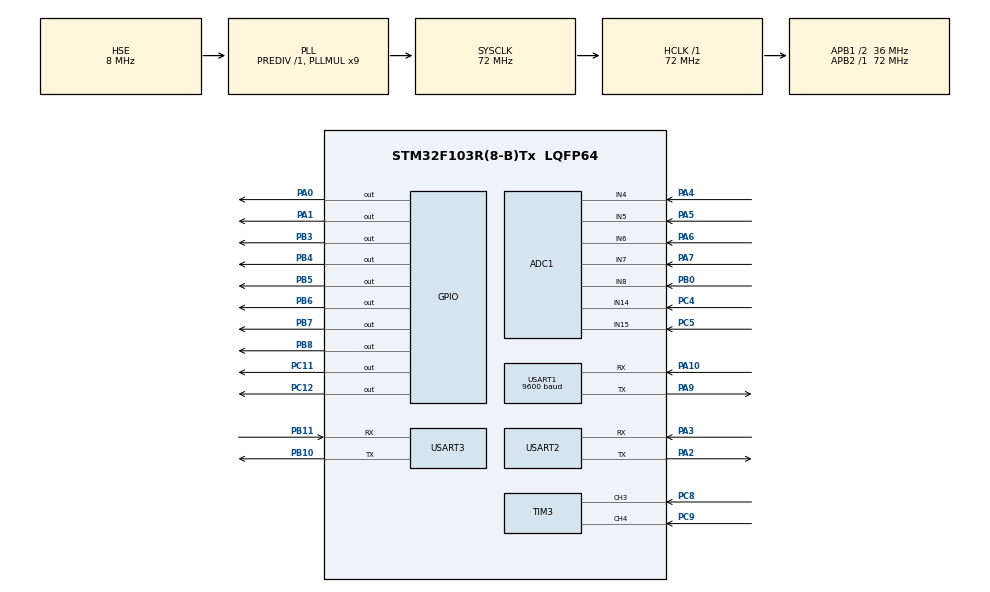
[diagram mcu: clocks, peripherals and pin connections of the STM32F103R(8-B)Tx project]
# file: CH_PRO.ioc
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ADC1.Channel-10\#ChannelRegularConversion=ADC_CHANNEL_6
ADC1.Channel-11\#ChannelRegularConversion=ADC_CHANNEL_7
ADC1.Channel-12\#ChannelRegularConversion=ADC_CHANNEL_8
ADC1.Channel-13\#ChannelRegularConversion=ADC_CHANNEL_14
ADC1.Channel-14\#ChannelRegularConversion=ADC_CHANNEL_15
ADC1.Channel-8\#ChannelRegularConversion=ADC_CHANNEL_4
ADC1.Channel-9\#ChannelRegularConversion=ADC_CHANNEL_5
ADC1.ContinuousConvMode=ENABLE
ADC1.DataAlign=ADC_DATAALIGN_RIGHT
ADC1.DiscontinuousConvMode=DISABLE
ADC1.EnableAnalogWatchDog=false
ADC1.EnableRegularConversion=ENABLE
ADC1.ExternalTrigConv=ADC_SOFTWARE_START
ADC1.InjNumberOfConversion=0
ADC1.NbrOfConversion=7
ADC1.NbrOfConversionFlag=1
ADC1.Rank-10\#ChannelRegularConversion=3
ADC1.Rank-11\#ChannelRegularConversion=4
ADC1.Rank-12\#ChannelRegularConversion=5
ADC1.Rank-13\#ChannelRegularConversion=6
ADC1.Rank-14\#ChannelRegularConversion=7
ADC1.Rank-8\#ChannelRegularConversion=1
ADC1.Rank-9\#ChannelRegularConversion=2
ADC1.SamplingTime-10\#ChannelRegularConversion=ADC_SAMPLETIME_28CYCLES_5
ADC1.SamplingTime-11\#ChannelRegularConversion=ADC_SAMPLETIME_28CYCLES_5
ADC1.SamplingTime-12\#ChannelRegularConversion=ADC_SAMPLETIME_28CYCLES_5
ADC1.SamplingTime-13\#ChannelRegularConversion=ADC_SAMPLETIME_28CYCLES_5
ADC1.SamplingTime-14\#ChannelRegularConversion=ADC_SAMPLETIME_28CYCLES_5
ADC1.SamplingTime-8\#ChannelRegularConversion=ADC_SAMPLETIME_28CYCLES_5
ADC1.SamplingTime-9\#ChannelRegularConversion=ADC_SAMPLETIME_28CYCLES_5
ADC1.ScanConvMode=ADC_SCAN_ENABLE
ADC1.master=1
Dma.Request0=USART1_RX
Dma.Request1=USART1_TX
Dma.USART1_RX.0.Direction=DMA_PERIPH_TO_MEMORY
Dma.USART1_RX.0.Instance=DMA1_Channel5
Dma.USART1_RX.0.MemDataAlignment=DMA_MDATAALIGN_BYTE
Dma.USART1_RX.0.MemInc=DMA_MINC_ENABLE
Dma.USART1_RX.0.Mode=DMA_NORMAL
Dma.USART1_RX.0.PeriphDataAlignment=DMA_PDATAALIGN_BYTE
Dma.USART1_RX.0.PeriphInc=DMA_PINC_DISABLE
Dma.USART1_RX.0.Priority=DMA_PRIORITY_VERY_HIGH
Dma.USART1_TX.1.Direction=DMA_MEMORY_TO_PERIPH
Dma.USART1_TX.1.Instance=DMA1_Channel4
Dma.USART1_TX.1.MemDataAlignment=DMA_MDATAALIGN_BYTE
Dma.USART1_TX.1.MemInc=DMA_MINC_ENABLE
Dma.USART1_TX.1.Mode=DMA_NORMAL
Dma.USART1_TX.1.PeriphDataAlignment=DMA_PDATAALIGN_BYTE
Dma.USART1_TX.1.PeriphInc=DMA_PINC_DISABLE
Dma.USART1_TX.1.Priority=DMA_PRIORITY_LOW
FREERTOS.INCLUDE_eTaskGetState=1
FREERTOS.Mutexes01=sendCmd,Dynamic,NULL
FREERTOS.Tasks01=helloTask,0,128,StartHelloTask,Default,NULL,Dynamic,NULL,NULL;cmdTask,-3,128,StartCmdTask,Default,NULL,Dynamic,NULL,NULL
FREERTOS.Timers01=myTimer01,Callback01,osTimerPeriodic,Default,NULL,Dynamic,NULL;myTimer02,Callback02,osTimerPeriodic,Default,NULL,Dynamic,NULL;myTimer03,Callback03,osTimerPeriodic,Default,NULL,Dynamic,NULL
FREERTOS.configTIMER_TASK_STACK_DEPTH=128
FREERTOS.configUSE_TIMERS=1
Mcu.Family=STM32F1
Mcu.Name=STM32F103R(8-B)Tx
Mcu.Package=LQFP64
NVIC.DMA1_Channel4_IRQn=true\:5\:0\:false\:false\:true\:true\:false
NVIC.DMA1_Channel5_IRQn=true\:5\:0\:false\:false\:true\:true\:false
NVIC.PriorityGroup=NVIC_PRIORITYGROUP_4
NVIC.TIM1_BRK_IRQn=true\:5\:0\:false\:false\:true\:true\:true
NVIC.TIM3_IRQn=true\:5\:0\:false\:false\:true\:true\:true
NVIC.TIM4_IRQn=true\:0\:0\:false\:false\:true\:false\:false
NVIC.TimeBase=TIM4_IRQn
NVIC.TimeBaseIP=TIM4
NVIC.USART1_IRQn=true\:5\:0\:false\:false\:true\:true\:true
PA0-WKUP.GPIO_Speed=GPIO_SPEED_FREQ_HIGH
PA0-WKUP.Signal=GPIO_Output
PA1.GPIO_Speed=GPIO_SPEED_FREQ_HIGH
PA1.Signal=GPIO_Output
PA10.Mode=Asynchronous
PA10.Signal=USART1_RX
PA13.Mode=Serial_Wire
PA13.Signal=SYS_JTMS-SWDIO
PA14.Mode=Serial_Wire
PA14.Signal=SYS_JTCK-SWCLK
PA2.Mode=Asynchronous
PA2.Signal=USART2_TX
PA3.Mode=Asynchronous
PA3.Signal=USART2_RX
PA4.Signal=ADCx_IN4
PA5.Signal=ADCx_IN5
PA6.Signal=ADCx_IN6
PA7.Signal=ADCx_IN7
PA9.Mode=Asynchronous
PA9.Signal=USART1_TX
PB0.Signal=ADCx_IN8
PB10.Mode=Asynchronous
PB10.Signal=USART3_TX
PB11.Mode=Asynchronous
PB11.Signal=USART3_RX
PB3.GPIO_Speed=GPIO_SPEED_FREQ_HIGH
PB3.Signal=GPIO_Output
PB4.GPIO_Speed=GPIO_SPEED_FREQ_HIGH
PB4.Signal=GPIO_Output
PB5.GPIO_Speed=GPIO_SPEED_FREQ_HIGH
PB5.Signal=GPIO_Output
PB6.GPIO_Speed=GPIO_SPEED_FREQ_HIGH
PB6.Signal=GPIO_Output
PB7.GPIO_Speed=GPIO_SPEED_FREQ_HIGH
PB7.Signal=GPIO_Output
PB8.GPIO_Speed=GPIO_SPEED_FREQ_HIGH
PB8.Signal=GPIO_Output
PC11.GPIO_Speed=GPIO_SPEED_FREQ_HIGH
PC11.Signal=GPIO_Output
PC12.GPIO_Speed=GPIO_SPEED_FREQ_HIGH
PC12.Signal=GPIO_Output
PC4.Signal=ADCx_IN14
PC5.Signal=ADCx_IN15
PC8.Signal=S_TIM3_CH3
PC9.Signal=S_TIM3_CH4
PD0-OSC_IN.Mode=HSE-External-Oscillator
PD0-OSC_IN.Signal=RCC_OSC_IN
PD1-OSC_OUT.Mode=HSE-External-Oscillator
PD1-OSC_OUT.Signal=RCC_OSC_OUT
ProjectManager.HeapSize=0x200
ProjectManager.StackSize=0x400
ProjectManager.TargetToolchain=EWARM
RCC.ADCPresc=RCC_ADCPCLK2_DIV6
RCC.AHBFreq_Value=72000000
RCC.APB1CLKDivider=RCC_HCLK_DIV2
RCC.APB1Freq_Value=36000000
RCC.APB1TimFreq_Value=72000000
RCC.APB2Freq_Value=72000000
RCC.APB2TimFreq_Value=72000000
RCC.HCLKFreq_Value=72000000
RCC.PLLMUL=RCC_PLL_MUL9
RCC.PLLSourceVirtual=RCC_PLLSOURCE_HSE
RCC.SYSCLKFreq_VALUE=72000000
RCC.SYSCLKSource=RCC_SYSCLKSOURCE_PLLCLK
RCC.USBFreq_Value=72000000
SH.ADCx_IN14.0=ADC1_IN14,IN14
SH.ADCx_IN15.0=ADC1_IN15,IN15
SH.ADCx_IN4.0=ADC1_IN4,IN4
SH.ADCx_IN5.0=ADC1_IN5,IN5
SH.ADCx_IN6.0=ADC1_IN6,IN6
SH.ADCx_IN7.0=ADC1_IN7,IN7
SH.ADCx_IN8.0=ADC1_IN8,IN8
SH.S_TIM3_CH3.0=TIM3_CH3,Input_Capture3_from_TI3
SH.S_TIM3_CH4.0=TIM3_CH4,Input_Capture4_from_TI4
TIM3.Channel-Input_Capture3_from_TI3=TIM_CHANNEL_3
TIM3.Channel-Input_Capture4_from_TI4=TIM_CHANNEL_4
USART1.BaudRate=9600
USART1.VirtualMode=VM_ASYNC
USART2.VirtualMode=VM_ASYNC
USART3.VirtualMode=VM_ASYNC
VP_FREERTOS_VS_ENABLE.Mode=Enabled
VP_SYS_VS_tim4.Mode=TIM4
VP_TIM1_VS_ClockSourceINT.Mode=Internal
VP_TIM2_VS_ClockSourceINT.Mode=Internal
board=CH_PRO

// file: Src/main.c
/**
  ******************************************************************************
  * @file           : main.c
  * @brief          : Main program body
  ******************************************************************************
  * This notice applies to any and all portions of this file
  * that are not between comment pairs USER CODE BEGIN and
  * USER CODE END. Other portions of this file, whether
  * inserted by the user or by software development tools
  * are owned by their respective copyright owners.
  *
  * Copyright (c) 2018 STMicroelectronics International N.V.
  * All rights reserved.
  *
  * Redistribution and use in source and binary forms, with or without
  * modification, are permitted, provided that the following conditions are met:
  *
  * 1. Redistribution of source code must retain the above copyright notice,
  *    this list of conditions and the following disclaimer.
  * 2. Redistributions in binary form must reproduce the above copyright notice,
  *    this list of conditions and the following disclaimer in the documentation
  *    and/or other materials provided with the distribution.
  * 3. Neither the name of STMicroelectronics nor the names of other
  *    contributors to this software may be used to endorse or promote products
  *    derived from this software without specific written permission.
  * 4. This software, including modifications and/or derivative works of this
  *    software, must execute solely and exclusively on microcontroller or
  *    microprocessor devices manufactured by or for STMicroelectronics.
  * 5. Redistribution and use of this software other than as permitted under
  *    this license is void and will automatically terminate your rights under
  *    this license.
  *
  * THIS SOFTWARE IS PROVIDED BY STMICROELECTRONICS AND CONTRIBUTORS "AS IS"
  * AND ANY EXPRESS, IMPLIED OR STATUTORY WARRANTIES, INCLUDING, BUT NOT
  * LIMITED TO, THE IMPLIED WARRANTIES OF MERCHANTABILITY, FITNESS FOR A
  * PARTICULAR PURPOSE AND NON-INFRINGEMENT OF THIRD PARTY INTELLECTUAL PROPERTY
  * RIGHTS ARE DISCLAIMED TO THE FULLEST EXTENT PERMITTED BY LAW. IN NO EVENT
  * SHALL STMICROELECTRONICS OR CONTRIBUTORS BE LIABLE FOR ANY DIRECT, INDIRECT,
  * INCIDENTAL, SPECIAL, EXEMPLARY, OR CONSEQUENTIAL DAMAGES (INCLUDING, BUT NOT
  * LIMITED TO, PROCUREMENT OF SUBSTITUTE GOODS OR SERVICES; LOSS OF USE, DATA,
  * OR PROFITS; OR BUSINESS INTERRUPTION) HOWEVER CAUSED AND ON ANY THEORY OF
  * LIABILITY, WHETHER IN CONTRACT, STRICT LIABILITY, OR TORT (INCLUDING
  * NEGLIGENCE OR OTHERWISE) ARISING IN ANY WAY OUT OF THE USE OF THIS SOFTWARE,
  * EVEN IF ADVISED OF THE POSSIBILITY OF SUCH DAMAGE.
  *
  ******************************************************************************
  */
#include "main.h"
#include "stm32f1xx_hal.h"
#include "cmsis_os.h"
#include "adc.h"
#include "dma.h"
#include "tim.h"
#include "usart.h"
#include "gpio.h"

/* USER CODE BEGIN PV */
/* Private variables ---------------------------------------------------------*/

/* USER CODE END PV */

void SystemClock_Config(void);
void MX_FREERTOS_Init(void);

/* USER CODE BEGIN PFP */
/* Private function prototypes -----------------------------------------------*/

/* USER CODE END PFP */

int main(void)
{

  /* MCU Configuration----------------------------------------------------------*/

  /* Reset of all peripherals, Initializes the Flash interface and the Systick. */
  HAL_Init();

  /* Configure the system clock */
  SystemClock_Config();

  /* Initialize all configured peripherals */
  MX_GPIO_Init();
  MX_DMA_Init();
  MX_ADC1_Init();
  MX_USART1_UART_Init();
  MX_USART2_UART_Init();
  MX_USART3_UART_Init();
  MX_TIM3_Init();
  MX_TIM2_Init();
  MX_TIM1_Init();

  /* Call init function for freertos objects (in freertos.c) */
  MX_FREERTOS_Init();

  /* Start scheduler */
  osKernelStart();

  /* We should never get here as control is now taken by the scheduler */

  /* Infinite loop */
  while (1)
  {

  }

}

void SystemClock_Config(void)
{

  RCC_OscInitTypeDef RCC_OscInitStruct;
  RCC_ClkInitTypeDef RCC_ClkInitStruct;
  RCC_PeriphCLKInitTypeDef PeriphClkInit;

    /**Initializes the CPU, AHB and APB busses clocks
    */
  RCC_OscInitStruct.OscillatorType = RCC_OSCILLATORTYPE_HSE;
  RCC_OscInitStruct.HSEState = RCC_HSE_ON;
  RCC_OscInitStruct.HSEPredivValue = RCC_HSE_PREDIV_DIV1;
  RCC_OscInitStruct.HSIState = RCC_HSI_ON;
  RCC_OscInitStruct.PLL.PLLState = RCC_PLL_ON;
  RCC_OscInitStruct.PLL.PLLSource = RCC_PLLSOURCE_HSE;
  RCC_OscInitStruct.PLL.PLLMUL = RCC_PLL_MUL9;
  if (HAL_RCC_OscConfig(&RCC_OscInitStruct) != HAL_OK)
  {
    _Error_Handler(__FILE__, __LINE__);
  }

    /**Initializes the CPU, AHB and APB busses clocks
    */
  RCC_ClkInitStruct.ClockType = RCC_CLOCKTYPE_HCLK|RCC_CLOCKTYPE_SYSCLK
                              |RCC_CLOCKTYPE_PCLK1|RCC_CLOCKTYPE_PCLK2;
  RCC_ClkInitStruct.SYSCLKSource = RCC_SYSCLKSOURCE_PLLCLK;
  RCC_ClkInitStruct.AHBCLKDivider = RCC_SYSCLK_DIV1;
  RCC_ClkInitStruct.APB1CLKDivider = RCC_HCLK_DIV2;
  RCC_ClkInitStruct.APB2CLKDivider = RCC_HCLK_DIV1;

  if (HAL_RCC_ClockConfig(&RCC_ClkInitStruct, FLASH_LATENCY_2) != HAL_OK)
  {
    _Error_Handler(__FILE__, __LINE__);
  }

  PeriphClkInit.PeriphClockSelection = RCC_PERIPHCLK_ADC;
  PeriphClkInit.AdcClockSelection = RCC_ADCPCLK2_DIV6;
  if (HAL_RCCEx_PeriphCLKConfig(&PeriphClkInit) != HAL_OK)
  {
    _Error_Handler(__FILE__, __LINE__);
  }

    /**Configure the Systick interrupt time
    */
  HAL_SYSTICK_Config(HAL_RCC_GetHCLKFreq()/1000);

    /**Configure the Systick
    */
  HAL_SYSTICK_CLKSourceConfig(SYSTICK_CLKSOURCE_HCLK);

  /* SysTick_IRQn interrupt configuration */
  HAL_NVIC_SetPriority(SysTick_IRQn, 15, 0);
}

void HAL_TIM_PeriodElapsedCallback(TIM_HandleTypeDef *htim)
{
  if (htim->Instance == TIM4) {
    HAL_IncTick();
  }
}

void _Error_Handler(char *file, int line)
{
  while(1)
  {
  }
}

/************************ (C) COPYRIGHT STMicroelectronics *****END OF FILE****/

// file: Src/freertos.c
/**
  ******************************************************************************
  * File Name          : freertos.c
  * Description        : Code for freertos applications
  ******************************************************************************
  * This notice applies to any and all portions of this file
  * that are not between comment pairs USER CODE BEGIN and
  * USER CODE END. Other portions of this file, whether
  * inserted by the user or by software development tools
  * are owned by their respective copyright owners.
  *
  * Copyright (c) 2018 STMicroelectronics International N.V.
  * All rights reserved.
  *
  * Redistribution and use in source and binary forms, with or without
  * modification, are permitted, provided that the following conditions are met:
  *
  * 1. Redistribution of source code must retain the above copyright notice,
  *    this list of conditions and the following disclaimer.
  * 2. Redistributions in binary form must reproduce the above copyright notice,
  *    this list of conditions and the following disclaimer in the documentation
  *    and/or other materials provided with the distribution.
  * 3. Neither the name of STMicroelectronics nor the names of other
  *    contributors to this software may be used to endorse or promote products
  *    derived from this software without specific written permission.
  * 4. This software, including modifications and/or derivative works of this
  *    software, must execute solely and exclusively on microcontroller or
  *    microprocessor devices manufactured by or for STMicroelectronics.
  * 5. Redistribution and use of this software other than as permitted under
  *    this license is void and will automatically terminate your rights under
  *    this license.
  *
  * THIS SOFTWARE IS PROVIDED BY STMICROELECTRONICS AND CONTRIBUTORS "AS IS"
  * AND ANY EXPRESS, IMPLIED OR STATUTORY WARRANTIES, INCLUDING, BUT NOT
  * LIMITED TO, THE IMPLIED WARRANTIES OF MERCHANTABILITY, FITNESS FOR A
  * PARTICULAR PURPOSE AND NON-INFRINGEMENT OF THIRD PARTY INTELLECTUAL PROPERTY
  * RIGHTS ARE DISCLAIMED TO THE FULLEST EXTENT PERMITTED BY LAW. IN NO EVENT
  * SHALL STMICROELECTRONICS OR CONTRIBUTORS BE LIABLE FOR ANY DIRECT, INDIRECT,
  * INCIDENTAL, SPECIAL, EXEMPLARY, OR CONSEQUENTIAL DAMAGES (INCLUDING, BUT NOT
  * LIMITED TO, PROCUREMENT OF SUBSTITUTE GOODS OR SERVICES; LOSS OF USE, DATA,
  * OR PROFITS; OR BUSINESS INTERRUPTION) HOWEVER CAUSED AND ON ANY THEORY OF
  * LIABILITY, WHETHER IN CONTRACT, STRICT LIABILITY, OR TORT (INCLUDING
  * NEGLIGENCE OR OTHERWISE) ARISING IN ANY WAY OUT OF THE USE OF THIS SOFTWARE,
  * EVEN IF ADVISED OF THE POSSIBILITY OF SUCH DAMAGE.
  *
  ******************************************************************************
  */

#include "FreeRTOS.h"
#include "task.h"
#include "cmsis_os.h"

/* USER CODE BEGIN Includes */

#include "App.h"

/* USER CODE END Includes */

osThreadId helloTaskHandle;
osThreadId cmdTaskHandle;
osTimerId myTimer01Handle;
osTimerId myTimer02Handle;
osTimerId myTimer03Handle;
osMutexId sendCmdHandle;

void StartHelloTask(void const * argument);
void StartCmdTask(void const * argument);
void Callback01(void const * argument);
void Callback02(void const * argument);
void Callback03(void const * argument);

void MX_FREERTOS_Init(void); /* (MISRA C 2004 rule 8.1) */

/* Hook prototypes */

/* Init FreeRTOS */

void MX_FREERTOS_Init(void) {

  /* Create the mutex(es) */
  /* definition and creation of sendCmd */
  osMutexDef(sendCmd);
  sendCmdHandle = osMutexCreate(osMutex(sendCmd));

  /* Create the timer(s) */
  /* definition and creation of myTimer01 */
  osTimerDef(myTimer01, Callback01);
  myTimer01Handle = osTimerCreate(osTimer(myTimer01), osTimerPeriodic, NULL);

  /* definition and creation of myTimer02 */
  osTimerDef(myTimer02, Callback02);
  myTimer02Handle = osTimerCreate(osTimer(myTimer02), osTimerPeriodic, NULL);

  /* definition and creation of myTimer03 */
  osTimerDef(myTimer03, Callback03);
  myTimer03Handle = osTimerCreate(osTimer(myTimer03), osTimerPeriodic, NULL);

  /* Create the thread(s) */
  /* definition and creation of helloTask */
  osThreadDef(helloTask, StartHelloTask, osPriorityNormal, 0, 128);
  helloTaskHandle = osThreadCreate(osThread(helloTask), NULL);

  /* definition and creation of cmdTask */
  osThreadDef(cmdTask, StartCmdTask, osPriorityIdle, 0, 128);
  cmdTaskHandle = osThreadCreate(osThread(cmdTask), NULL);

}

/* StartHelloTask function */
void StartHelloTask(void const * argument)
{

  /* USER CODE BEGIN StartHelloTask */
    /* Infinite loop */
    for(;;)
    {
        printf("hello");
        osDelay(10);
    }
  /* USER CODE END StartHelloTask */
}

/* StartCmdTask function */
void StartCmdTask(void const * argument)
{
  /* USER CODE BEGIN StartCmdTask */
    /* Infinite loop */
    for(;;)
    {
        printf("world\r\n");
        osDelay(1);

    }
  /* USER CODE END StartCmdTask */
}

/* Callback01 function */
void Callback01(void const * argument)
{
}

/* Callback02 function */
void Callback02(void const * argument)
{
}

/* Callback03 function */
void Callback03(void const * argument)
{
}

/************************ (C) COPYRIGHT STMicroelectronics *****END OF FILE****/
